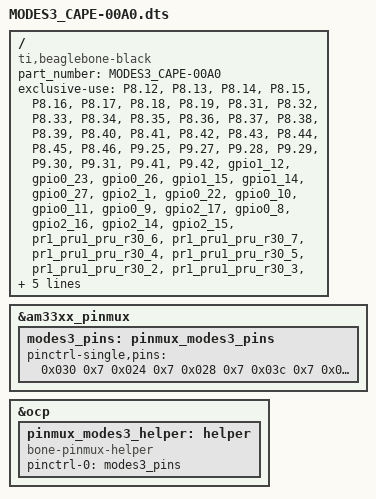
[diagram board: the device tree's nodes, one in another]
/dts-v1/;
/plugin/;

/{
    compatible = "ti,beaglebone-black";
    part_number = "MODES3_CAPE-00A0";

	exclusive-use =
		"P8.12",
		"P8.13",
		"P8.14",
		"P8.15",
		"P8.16",
		"P8.17",
		"P8.18",
		"P8.19",
		"P8.31",
		"P8.32",
		"P8.33",
		"P8.34",
		"P8.35",
		"P8.36",
		"P8.37",
		"P8.38",
		"P8.39",
		"P8.40",
		"P8.41",
		"P8.42",
		"P8.43",
		"P8.44",
		"P8.45",
		"P8.46",
		"P9.25",
		"P9.27",
		"P9.28",
		"P9.29",
		"P9.30",
		"P9.31",
		"P9.41",
		"P9.42",
		"gpio1_12",
		"gpio0_23",
		"gpio0_26",
		"gpio1_15",
		"gpio1_14",
		"gpio0_27",
		"gpio2_1",
		"gpio0_22",
		"gpio0_10",
		"gpio0_11",
		"gpio0_9",
		"gpio2_17",
		"gpio0_8",
		"gpio2_16",
		"gpio2_14",
		"gpio2_15",
		"pr1_pru1_pru_r30_6",
		"pr1_pru1_pru_r30_7",
		"pr1_pru1_pru_r30_4",
		"pr1_pru1_pru_r30_5",
		"pr1_pru1_pru_r30_2",
		"pr1_pru1_pru_r30_3",
		"pr1_pru1_pru_r30_0",
		"pr1_pru1_pru_r30_1",
		"pr1_pru1_pru_r31_7",
		"pr1_pru1_pru_r31_5",
		"pr1_pru1_pru_r31_3",
		"pr1_pru1_pru_r31_1",
		"pr1_pru1_pru_r31_2",
		"pr1_pru1_pru_r31_0",
		"pr1_pru1_pru_r31_6",
		"pr1_pru1_pru_r31_4";

    fragment@0 {
        target = <&am33xx_pinmux>;
        __overlay__ {
            modes3_pins: pinmux_modes3_pins {
                pinctrl-single,pins = <
                    // GPIO - P8_12..P8_19
                    0x030 0x7
                    0x024 0x7
                    0x028 0x7
                    0x03c 0x7
                    0x038 0x7
                    0x02c 0x7
                    0x08c 0x7
                    0x020 0x7
                    // GPIO - P8_31..P8_38
                    0x0d8 0x7
                    0x0dc 0x7
                    0x0d4 0x7
                    0x0cc 0x7
                    0x0d0 0x7
                    0x0c8 0x7
                    0x0c0 0x7
                    0x0c4 0x7
                    // PRU1 - P8_39..P8_46
                    0x0b8 0x5
                    0x0bc 0x5
                    0x0b0 0x5
                    0x0b4 0x5
                    0x0a8 0x5
                    0x0ac 0x5
                    0x0a0 0x5
                    0x0a4 0x5
                    // PRU0 - P9_25..P9_31,P9_41,P9_42
                    0x1ac 0x5
                    0x1a4 0x5
                    0x19c 0x5
                    0x194 0x5
                    0x198 0x5
                    0x190 0x5
					0x1b4 0x5
					0x164 0x5
					// DISABLE
					0x1a8 0x2f
					0x1a0 0x2f
                >;
            };
        };
    };

    fragment@1 {
        target = <&ocp>;
        __overlay__ {
            pinmux_modes3_helper: helper {
                compatible = "bone-pinmux-helper";
                status = "okay";
                pinctrl-names = "default";
                pinctrl-0 = <&modes3_pins>;
            };
        };
    };
};
